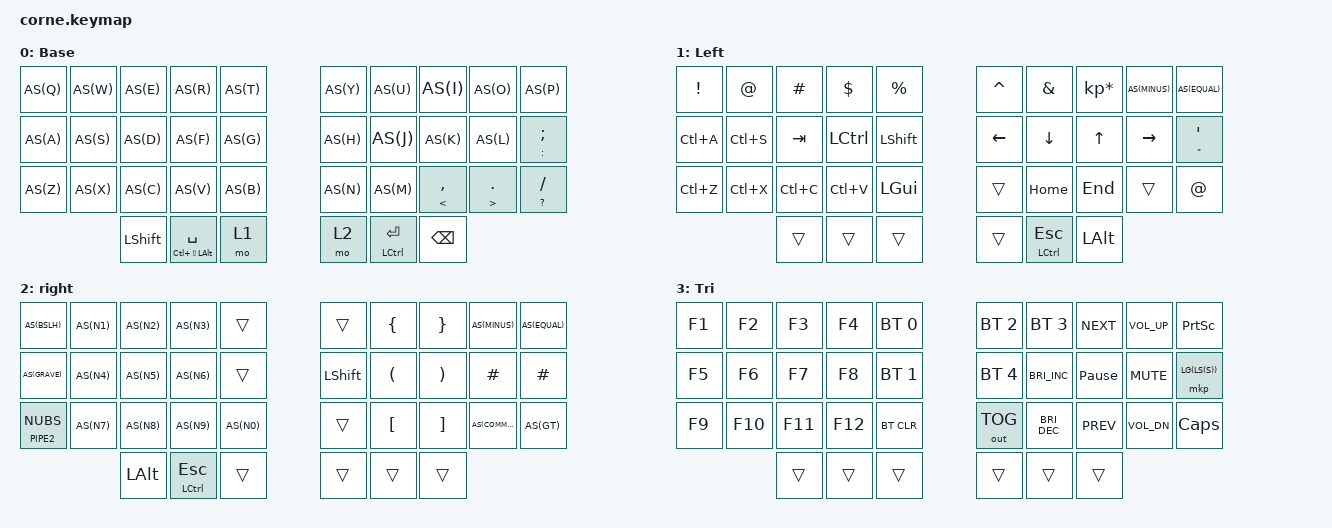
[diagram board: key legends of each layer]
/*
 * Copyright (c) 2020 The ZMK Contributors
 *
 * SPDX-License-Identifier: MIT
 */

#include <behaviors.dtsi>
#include <dt-bindings/zmk/keys.h>
#include <dt-bindings/zmk/bt.h>
#include <dt-bindings/zmk/outputs.h>

&mt {
    tapping-term-ms = <201>;
    flavor = "tap-preferred";
 };

&sk {
     release-after-ms = <2000>;
     quick-release;
 };

#define AS(keycode) &as LS(keycode) keycode

/ {
    chosen {
      zmk,matrix_transform = &five_column_transform;
    };

    behaviors {
        htm: hold_tap_mod {
            compatible = "zmk,behavior-hold-tap";
            #binding-cells = <2>;
            tapping_term_ms = <200>;
            quick_tap_ms = <0>;
            flavor = "tap-preferred";
            bindings = <&kp>, <&kp>;
        };
        as: auto_shift {
            compatible = "zmk,behavior-hold-tap";
            #binding-cells = <2>;
            tapping_term_ms = <300>;
            quick_tap_ms = <0>;
            flavor = "tap-preferred";
            bindings = <&kp>, <&kp>;
        };
    };

    conditional_layers {
        compatible = "zmk,conditional-layers";
        tri_layer {
            if-layers = <1 2>;
            then-layer = <3>;
        };
    };
        keymap {
                compatible = "zmk,keymap";

                default_layer {
// -----------------------------------------------------------------------------------------
// |  Q  |  W  |  E  |  R  |  T  |____|  Y  |  U   |  I   |  O   |  P  |
// |  A  |  S  |  D  |  F  |  G  |____|  H  |  J   |  K   |  L   |  ;: |
// |  Z  |  X  |  C  |  V  |  B  |____|  N  |  M   |  ,<  |  .>  |  /? |
//        | LSHFT | SPC (MEH) | LWR |____| RSE |  ENT(LCTL) | BSPC |
                        display-name = "Base";
                        bindings = <
   AS(Q) AS(W) AS(E) AS(R) AS(T)     AS(Y)   AS(U)  AS(I)     AS(O)     AS(P)
   AS(A) AS(S) AS(D) AS(F) AS(G)     AS(H)   AS(J)  AS(K)     AS(L)     &htm COLON SEMI
   AS(Z) AS(X) AS(C) AS(V) AS(B)     AS(N)   AS(M)  &htm LT COMMA  &htm GT DOT  &htm QMARK FSLH
        &kp LSHFT &mt LC(LS(LALT)) SPC &mo 1     &mo 2   &htm LCTL RET  &kp BSPC
                        >;
                };

                left_layer {
// @ and " symbols are swapped                     
// -----------------------------------------------------------------------------------------
// | !   |  "  |  £  |  $  |  %  |____|  ^  |  &  |  *  |  -_ |  =+ |     
// |LC(A)|LC(S)| TAB | LC  |LSHFT|____| LFT | DWN |  UP | RGT |  '@ |
// |LC(Z)|LC(x)|LC(C)|LC(V)| GUI |____|   ! | HME | END |  %  |  "  |
//               | --- | --- | --- |____|     | ESC(LCTL) | LALT |
                        display-name = "Left";
                        bindings = <
   &kp EXCL &kp AT   &kp HASH &kp DLLR &kp PRCNT        &kp CARET &kp AMPS  &kp KP_MULTIPLY AS(MINUS)   AS(EQUAL)
   &kp LC(A)   &kp LC(S) &kp TAB  &kp LCTL  &kp LSHFT   &kp LEFT  &kp DOWN  &kp UP          &kp RIGHT &htm DQT APOS
   &kp LC(Z)   &kp LC(X) &kp LC(C) &kp LC(V) &kp LGUI     &trans    &kp HOME  &kp END         &trans    &kp AT
                &trans   &trans    &trans            &trans  &htm LCTL ESC  &kp LALT 
                        >;
                };

                right_layer {
// -----------------------------------------------------------------------------------------
// | #~  |  1! |  2" |  3£  |     |____|     |  {  |  }  |  -_ |      |
// | `¬  |  4$ |  5% |  6^  |     |____|LSHFT|  (  |  )  |  £  |   ~  |
// | \|  |  7& |  8* |  9(  |  0) |____|     |  [  |  ]  |  ,< |  .>  |
//     | LSHIFT | ESC(LCTL) | --- |____| --- | --- | --- |
                        display-name = "right";
                        bindings = <

   AS(BSLH)         AS(N1)    AS(N2)    AS(N3)  &trans        &trans    &kp LBRC  &kp RBRC  AS(MINUS)   AS(EQUAL)
   AS(GRAVE)        AS(N4)    AS(N5)    AS(N6)  &trans        &kp LSHFT &kp LPAR  &kp RPAR  &kp HASH  &kp POUND
   &htm PIPE2 NUBS  AS(N7)    AS(N8)    AS(N9)  AS(N0)        &trans    &kp LBKT  &kp RBKT  AS(COMMA)  AS(GT)
                       &kp LALT  &htm LCTL ESC   &trans     &trans   &trans    &trans
                        >;
                };

                tri_layer {
//╭──────────┬──────────┬──────────┬───────────┬────────────╮   ╭────────────┬────────────┬──────────┬───────────┬──────────╮
//│  F1      │  F2      │  F3      │  F4       │ PROFILE 0  │   │ PROFILE 2  │ PROFILE 3  │ NEXTSONG │ VOL UP    │PRINT SCRN│
//├──────────┼──────────┼──────────┼───────────┼────────────┤   ├────────────┼────────────┼──────────┤───────────┼──────────┤
//│  F5      │  F6      │  F7      │  F8       │ PROFILE 1  │   │ PROFILE 4  │`INC BRIGHT`│PAUSEMUSIC│ VOL MUTE  │ LG(LS(S))│
//├──────────┼──────────┼──────────┼───────────┼────────────┤   ├────────────┼────────────┼──────────┤───────────┼──────────┤
//│  F9      │  F10     │  F11     │  F12      │  CLEAR BT  │   │`TOGGLEOUT` │`DEC BRIGHT`│ PREVSONG │  VOL DOWN │ CAPSLOCK │
//╰──────────┴──────────┴──────────┼───────────┼────────────┤   ├────────────┼────────────┼──────────┴───────────┴──────────╯
//                                  ╰───────────┴──────────╯   ╰──────────┴────────────╯
                        display-name = "Tri";
                        bindings = <

   &kp F1    &kp F2  &kp F3  &kp F4  &bt BT_SEL 0        &bt BT_SEL 2 &bt BT_SEL 3           &kp C_NEXT      &kp C_VOL_UP &kp PSCRN
   &kp F5    &kp F6  &kp F7  &kp F8  &bt BT_SEL 1        &bt BT_SEL 4 &kp C_BRIGHTNESS_INC   &kp PAUSE_BREAK &kp C_MUTE   &mkp LG(LS(S))
   &kp F9   &kp F10  &kp F11 &kp F12 &bt BT_CLR          &out OUT_TOG &kp C_BRIGHTNESS_DEC   &kp C_PREV      &kp C_VOL_DN &kp CAPS
                     &trans  &trans  &trans              &trans       &trans                 &trans
                        >;
                };
        };
};
